# STM32F072x register map
File version: 1.0
Registers are 32-bit, read-write, reset 0x0 unless marked. A register's access mark holds for its fields unless they carry their own. Offsets are from the block's base; lines under a group give offsets from that group; [hi:lo] are bit positions; {n}, {i} and the like mark numbered series; 'fields as' and 'values as' point back to an identical list; <NAME> marks a mode.

## Memory map
0x40004000 CRC2 size 0x400 — blub
0x40004400 CRC3 size 0x400 — foo bar
0x40023000 CRC1 size 0x400 — cyclic redundancy check calculation unit
0x48001400 GPIOF size 0x400 — General-purpose I/Os

## CRC1 — cyclic redundancy check calculation unit
Base 0x40023000
Same registers: CRC2 0x40004000, CRC3 0x40004400
0x00 DR reset 0xFFFFFFFF — Data register
  [31:0] DR — Data register bits
0x04 IDR — Independent data register
  [7:0] IDR — General-purpose 8-bit data register bits
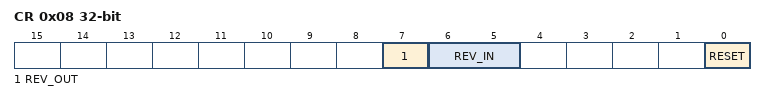
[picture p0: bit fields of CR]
0x08 CR — Control register
  [7] REV_OUT — Reverse output data
  [6:5] REV_IN — Reverse input data
  [0] RESET — reset bit
0x0C INIT reset 0xFFFFFFFF — Initial CRC value
  [31:0] INIT — Programmable initial CRC value

## GPIOF — General-purpose I/Os
Base 0x48001400
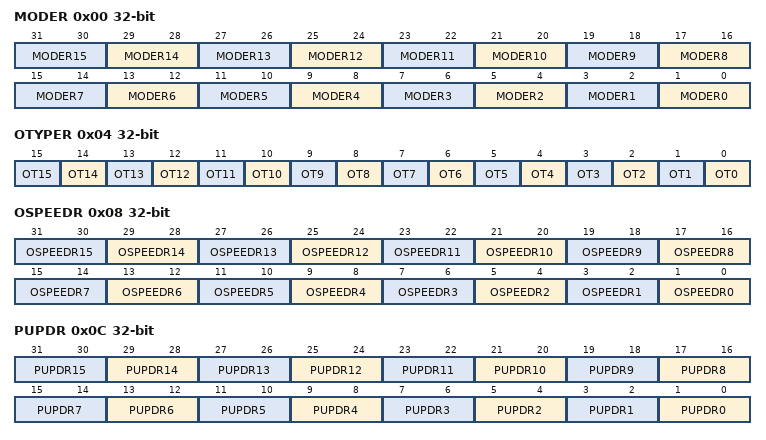
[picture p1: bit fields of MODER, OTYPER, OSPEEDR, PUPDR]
0x00 MODER — GPIO port mode register
  [2n+1:2n] MODER{n} (n=0..15) — Port x configuration bits (y = 0..15)
0x04 OTYPER — GPIO port output type register
  [n] OT{n} (n=0..15) — Port x configuration bit {n}
0x08 OSPEEDR — GPIO port output speed register
  [2n+1:2n] OSPEEDR{n} (n=0..15) — Port x configuration bits (y = 0..15)
0x0C PUPDR — GPIO port pull-up/pull-down register
  [2n+1:2n] PUPDR{n} (n=0..15) — Port x configuration bits (y = 0..15)
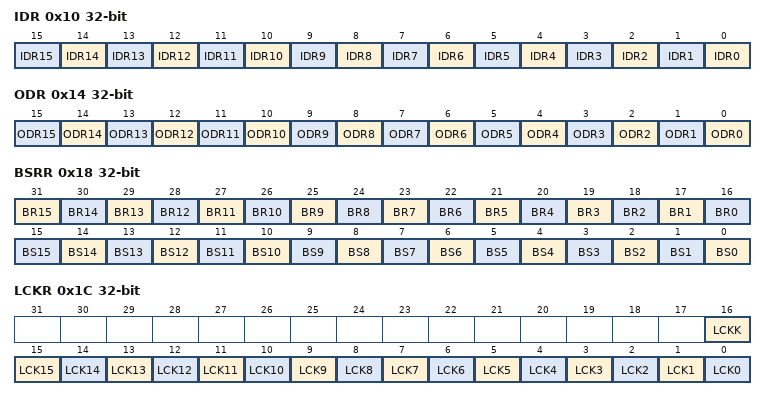
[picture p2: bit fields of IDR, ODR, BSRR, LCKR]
0x10 IDR ro — GPIO port input data register
  [n] IDR{n} (n=0..15) — Port input data (y = 0..15)
0x14 ODR — GPIO port output data register
  [n] ODR{n} (n=0..15) — Port output data (y = 0..15)
0x18 BSRR wo — GPIO port bit set/reset register
  [n+16] BR{n} (n=1..15) — Port x reset bit y (y = 0..15)
  [16] BR0 — Port x set bit y (y= 0..15)
  [n] BS{n} (n=0..15) — Port x set bit y (y= 0..15)
0x1C LCKR — GPIO port configuration lock register
  [16] LCKK — Port x lock bit y
  [n] LCK{n} (n=0..15) — Port x lock bit y (y= 0..15)
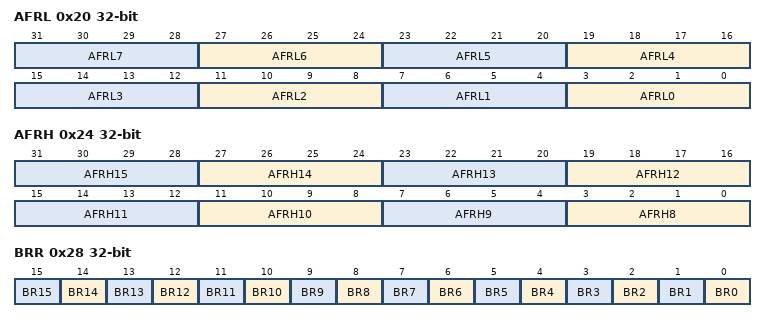
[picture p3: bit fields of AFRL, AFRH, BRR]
0x20 AFRL — GPIO alternate function low register
  [4n+3:4n] AFRL{n} (n=0..7) — Alternate function selection for port x bit y (y = 0..7)
0x24 AFRH — GPIO alternate function high register
  [4n-29:4n-32] AFRH{n} (n=8..15) — Alternate function selection for port x bit y (y = 8..15)
0x28 BRR wo — Port bit reset register
  [n] BR{n} (n=0..15) — Port x Reset bit y
